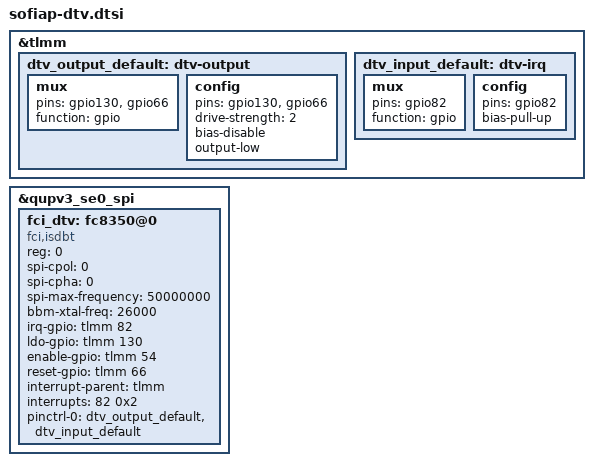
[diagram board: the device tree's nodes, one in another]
/*
 * Copyright (c) 2019, The Linux Foundation. All rights reserved.
 *
 * This program is free software; you can redistribute it and/or modify
 * it under the terms of the GNU General Public License version 2 and
 * only version 2 as published by the Free Software Foundation.
 *
 * This program is distributed in the hope that it will be useful,
 * but WITHOUT ANY WARRANTY; without even the implied warranty of
 * MERCHANTABILITY or FITNESS FOR A PARTICULAR PURPOSE.  See the
 * GNU General Public License for more details.
 */

&tlmm {
	dtv_output_default: dtv-output {
		mux {
			/* enable, reset */
			pins = "gpio130", "gpio66";
			function = "gpio";
		};
		config {
			pins = "gpio130", "gpio66";
			drive-strength = <2>; /* 2 MA */
			bias-disable ; /* No PULL */
			output-low;
		};
	};

	dtv_input_default: dtv-irq {
		mux {
			pins = "gpio82";
			function = "gpio";
		};
		config {
			pins = "gpio82";
			bias-pull-up; /* pull up */
		};
	};
};

&qupv3_se0_spi {
	status = "ok";

	fci_dtv: fc8350@0 {
		status = "ok";
		compatible = "fci,isdbt";
		reg = <0>;
		spi-cpol = <0>;
		spi-cpha = <0>;
		spi-max-frequency = <50000000>;
		bbm-xtal-freq = <26000>;
		irq-gpio = <&tlmm 82 0>;
		ldo-gpio = <&tlmm 130 0>;
		enable-gpio = <&tlmm 54 0>;
		reset-gpio = <&tlmm 66 0>;
		interrupt-parent = <&tlmm>;
		interrupts = <82 0x2>;
		interrupt-names = "dtv_irq";
		pinctrl-names = "default";
		pinctrl-0 = <&dtv_output_default &dtv_input_default>;
	};
};
